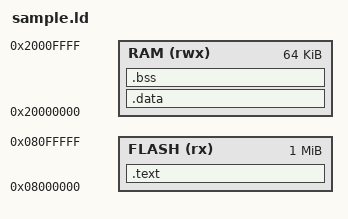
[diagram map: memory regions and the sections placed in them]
INPUT(& &)

MEMORY
{
  FLASH (rx)  : ORIGIN = 0x08000000, LENGTH = 1M
  RAM   (rwx) : ORIGIN = 0x20000000, LENGTH = 64k
}

ENTRY(reset_ISR)
_estack = ORIGIN(RAM) + LENGTH(RAM);

SECTIONS
{
  .text :
  {
    _stext = .;
    KEEP(*(.vectors))
    *(.text*)
    *(.rodata*)
    _etext = .;
  } > FLASH

  .data : AT(_etext)
  {
    _sdata = .;
    *(.data*)
    _edata = .;
  } > RAM

  .bss :
  {
    _sbss = .;
    *(.bss*)
    *(COMMON)
    _ebss = .;
  } > RAM
}


